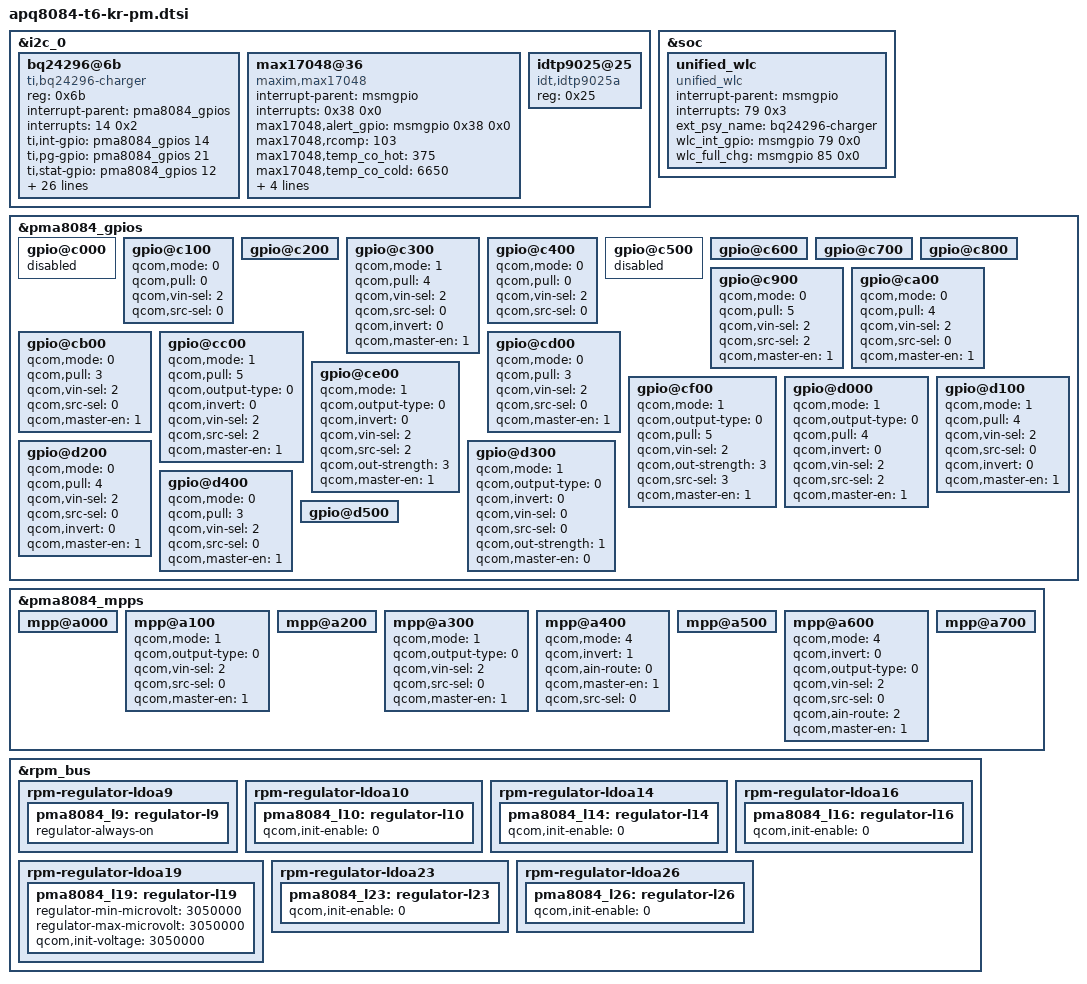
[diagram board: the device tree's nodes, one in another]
/* Copyright (c) 2012, Code Aurora Forum. All rights reserved.
 *
 * This program is free software; you can redistribute it and/or modify
* it under the terms of the GNU General Public License version 2 and
* only version 2 as published by the Free Software Foundation.
*
* This program is distributed in the hope that it will be useful,
* but WITHOUT ANY WARRANTY; without even the implied warranty of
* MERCHANTABILITY or FITNESS FOR A PARTICULAR PURPOSE.  See the
* GNU General Public License for more details.
*/
&i2c_0 {
	bq24296@6b {
		status = "ok";
		compatible = "ti,bq24296-charger";
		reg = <0x6b>;
		interrupt-parent = <&pma8084_gpios>;
		interrupts = <14 0x2>;
		ti,int-gpio = <&pma8084_gpios 14 0x0>;
		ti,pg-gpio = <&pma8084_gpios 21 0x0>;
		ti,stat-gpio = <&pma8084_gpios 12 0x02>;
		ti,ext-chg-en-gpio = <&pma8084_gpios 18 0x0>;
		ti,otg-en-gpio = <&msmgpio 127 0x0>;
		ti,chg-current-ma = <2000>;
		ti,term-current-ma = <128>;
		ti,vbat-max-mv = <4352>;
		ti,pre-chg-current-ma = <512>;
		ti,sys-vmin-mv = <3600>;
		ti,vin-limit-mv = <4520>;
		ti,icl-vbus-mv = <4400>;
		ti,pre-input-current-ma = <1000>;

		lge,no-init-cable = <0 0 0>;
		lge,cable-mhl-1k = <5000 500 500>;
		lge,cable-u-28p7k = <5500 2000 500>;
		lge,cable-28p7k = <6000 2000 500>;
		lge,cable-56k = <178000 2000 1500>;
		lge,cable-100k = <178500 2000 500>;
		lge,cable-130k = <340000 500 500>;
		lge,cable-180k = <400000 2000 500>;
		lge,cable-200k = <410000 2000 500>;
		lge,cable-220k = <485000 2000 500>;
		lge,cable-270k = <560000 2000 500>;
		lge,cable-330k = <735000 2000 500>;
		lge,cable-620k = <955000 2000 500>;
		lge,cable-910k = <1200000 2000 1500>;
		lge,cable-none = <1900000 2000 500>;

		qcom,bq24296-vadc = <&pma8084_vadc>;
	};
};

&i2c_0 {
	/* BLSP1 QUP3 */
	max17048@36 {
		compatible = "maxim,max17048";
		interrupt-parent = <&msmgpio>;
		interrupts = <0x38 0x0>;
		max17048,alert_gpio = <&msmgpio 0x38 0x0>;
		max17048,rcomp = <103>;
		max17048,temp_co_hot = <375>;
		max17048,temp_co_cold = <6650>;
		max17048,alert_threshold = <0x2>;
		max17048,full_design = <0xbb8>;
		max17048,empty = <0>;
		reg = <0x36>;
	};

	idtp9025@25 {
		status = "ok";
		compatible = "idt,idtp9025a";
		reg = <0x25>;
	};
};

&soc {
	unified_wlc {
		status = "ok";
		compatible = "unified_wlc";
		interrupt-parent = <&msmgpio>;
		interrupts = <79 0x3>;
		ext_psy_name = "bq24296-charger";
		wlc_int_gpio = <&msmgpio 79 0x0>;
		wlc_full_chg = <&msmgpio 85 0x0>;
	};
};

&pma8084_gpios {
	gpio@c000 { /* GPIO 1 */
		status = "disable";
	};

	gpio@c100 { /* GPIO 2 */
		status = "ok";           /* KYPD_VOL_UP_N */
		qcom,mode = <0>;
		qcom,pull = <0>;
		qcom,vin-sel = <2>;
		qcom,src-sel = <0>;
	};

	gpio@c200 { /* GPIO 3 */
		status = "ok";           /* DIVCLK1_REQ */
	};

	gpio@c300 { /* GPIO 4 */
		status = "ok";           /* BT_RESET_N */
		qcom,mode = <1>;         /* Digital output*/
		qcom,pull = <4>;         /* Pulldown 10uA */
		qcom,vin-sel = <2>;      /* VIN2 */
		qcom,src-sel = <0>;      /* GPIO */
		qcom,invert = <0>;       /* Invert */
		qcom,master-en = <1>;    /* Enable GPIO */
	};

	gpio@c400 { /* GPIO 5 */
		status = "ok";           /* KYPD_VOL_DOWN_N */
		qcom,mode = <0>;
		qcom,pull = <0>;
		qcom,vin-sel = <2>;
		qcom,src-sel = <0>;
	};

	gpio@c500 { /* GPIO 6 */
		status = "disable";
	};

	gpio@c600 { /* GPIO 7 */
		status = "ok";           /* RED_LED_DRV */
	};

	gpio@c700 { /* GPIO 8 */
		status = "ok";           /* GREEN_LED_DRV */
	};

	gpio@c800 { /* GPIO 9 */
		status = "ok";           /* BLUE_LED_DRV */
	};

	gpio@c900 { /* GPIO 10 */
		status = "ok";           /* NFC_CLK_REQ */
		qcom,mode = <0>;         /* QPNP_PIN_MODE_DIG_IN */
		qcom,pull = <5>;         /* QPNP_PIN_PULL_NO */
		qcom,vin-sel = <2>;      /* QPNP_PIN_VIN2 */
		qcom,src-sel = <2>;      /* QPNP_PIN_SEL_FUNC_1 */
		qcom,master-en = <1>;
	};

	gpio@ca00 { /* GPIO 11 */
		status = "ok";           /* SLIMPORT_CBL_DET */
		qcom,mode = <0>;         /* QPNP_PIN_MODE_DIG_IN */
		qcom,pull = <4>;         /* QPNP_PIN_PULL_DN */
		qcom,vin-sel = <2>;      /* QPNP_PIN_VIN2 */
		qcom,src-sel = <0>;      /* QPNP_PIN_SEL_FUNC_1 */
		qcom,master-en = <1>;
	};

	gpio@cb00 { /* GPIO 12 */
		status = "ok";           /* EXT_CHG_STAT */
		qcom,mode = <0>;         /* QPNP_PIN_MODE_DIG_IN */
		qcom,pull = <3>;         /* QPNP_PIN_GPIO_PULL_UP_1P5_30 */
		qcom,vin-sel = <2>;      /* QPNP_PIN_VIN2 */
		qcom,src-sel = <0>;      /* QPNP_PIN_SEL_FUNC_CONSTANT */
		qcom,master-en = <1>;
	};

	gpio@cc00 { /* GPIO 13 */
		status = "ok";           /* ANX_PDWN_CTL */
		qcom,mode = <1>;         /* Digital output */
		qcom,pull = <5>;         /* QPNP_PIN_PULL_NO */
		qcom,output-type = <0>;  /* CMOS logic */
		qcom,invert = <0>;       /* Output low initially */
		qcom,vin-sel = <2>;      /* VIN 2 */
		qcom,src-sel = <2>;      /* Function 1 */
		qcom,master-en = <1>;    /* Enable GPIO */
	};

	gpio@cd00 { /* GPIO 14 */
		status = "ok";           /* EXT_CHG_INT */
		qcom,mode = <0>;         /* QPNP_PIN_MODE_DIG_IN */
		qcom,pull = <3>;         /* QPNP_PIN_GPIO_PULL_UP_1P5_30 */
		qcom,vin-sel = <2>;      /* QPNP_PIN_VIN2 */
		qcom,src-sel = <0>;      /* QPNP_PIN_SEL_FUNC_CONSTANT */
		qcom,master-en = <1>;
	};

	gpio@ce00 { /* GPIO 15 */
		status = "ok";           /* CODEC_MCLK */
		qcom,mode = <1>;         /* Digital output */
		qcom,output-type = <0>;  /* CMOS logic */
		qcom,invert = <0>;       /* Output low initially */
		qcom,vin-sel = <2>;      /* VIN 2 */
		qcom,src-sel = <2>;      /* Function 1 */
		qcom,out-strength = <3>; /* High */
		qcom,master-en = <1>;    /* Enable GPIO */
	};

	gpio@cf00 { /* GPIO 16 */
		status = "ok";           /* WIFI_SLEEP_CLK, T6 BT Bringup kyungrin.seo */
		qcom,mode = <1>;
		qcom,output-type = <0>;
		qcom,pull = <5>;
		qcom,vin-sel = <2>;
		qcom,out-strength = <3>;
		qcom,src-sel = <3>;
		qcom,master-en = <1>;

	};

	gpio@d000 { /* GPIO 17 */
		status = "ok";           /* SLIMPORT_RESET_N */
		qcom,mode = <1>;         /* Digital output */
		qcom,output-type = <0>;  /* CMOS logic */
		qcom,pull = <4>;         /* QPNP_PIN_PULL_DN */
		qcom,invert = <0>;       /* Output low initially */
		qcom,vin-sel = <2>;      /* VIN 2 */
		qcom,src-sel = <2>;      /* Function 1 */
		qcom,master-en = <1>;    /* Enable GPIO */
	};

	gpio@d100 { /* GPIO 18 */
		status = "ok";           /* EXT_CHG_EN */
		qcom,mode = <1>;         /* Digital output*/
		qcom,pull = <4>;         /* Pulldown 10uA */
		qcom,vin-sel = <2>;      /* VIN2 */
		qcom,src-sel = <0>;      /* GPIO */
		qcom,invert = <0>;       /* Invert */
		qcom,master-en = <1>;    /* Enable GPIO */
	};

	gpio@d200 { /* GPIO 19 */
		status = "ok";           /* BOOST_BYP_BYP_N */
		qcom,mode = <0>;         /* QPNP_PIN_MODE_DIG_IN */
		qcom,pull = <4>;         /* QPNP_PIN_PULL_DN */
		qcom,vin-sel = <2>;      /* VIN2 */
		qcom,src-sel = <0>;      /* GPIO */
		qcom,invert = <0>;       /* Invert */
		qcom,master-en = <1>;    /* Enable GPIO */
	};

	gpio@d300 { /* GPIO 20 */
		status = "ok";           /* WIFI_SLEEP_CLK */
		qcom,mode = <1>;         /* Digital output */
		qcom,output-type = <0>;  /* CMOS logic */
		qcom,invert = <0>;       /* Do not invert the output */
		qcom,vin-sel = <0>;      /* VPH_PWR */
		qcom,src-sel = <0>;      /* GPIO */
		qcom,out-strength = <1>; /* High drive strength */
		qcom,master-en = <0>;    /* Enable GPIO */          /* WIFI_SLEEP_CLK, T6 WiFi Bringup. Set master-en = <0>;  */
	};

	gpio@d400 { /* GPIO 21 */
		status = "ok";           /* EXT_CHG_PG */
		qcom,mode = <0>;         /* QPNP_PIN_MODE_DIG_IN */
		qcom,pull = <3>;         /* QPNP_PIN_GPIO_PULL_UP_1P5_30 */
		qcom,vin-sel = <2>;      /* QPNP_PIN_VIN2 */
		qcom,src-sel = <0>;      /* QPNP_PIN_SEL_FUNC_CONSTANT */
		qcom,master-en = <1>;
	};

	gpio@d500 { /* GPIO 22 */
		status = "ok";           /* BATT_UIM_ALARM */
	};
};

&pma8084_mpps {
	mpp@a000 { /* MPP 1 */
	};

	mpp@a100 { /* MPP 2 */
		qcom,mode = <1>;         /* Digital output */
		qcom,output-type = <0>;  /* CMOS logic */
		qcom,vin-sel = <2>;      /* VIN 2 */
		qcom,src-sel = <0>;      /* Constant */
		qcom,master-en = <1>;    /* Enable GPIO */
	};

	mpp@a200 { /* MPP 3 */
	};

	mpp@a300 { /* MPP 4 */
		qcom,mode = <1>;         /* Digital output */
		qcom,output-type = <0>;  /* CMOS logic */
		qcom,vin-sel = <2>;      /* VIN 2 */
		qcom,src-sel = <0>;      /* Constant */
		qcom,master-en = <1>;    /* Enable GPIO */
	};

	mpp@a400 { /* MPP 5 */
		qcom,mode = <4>;		/* QPNP_PIN_MODE_AIN */
		qcom,invert = <1>;		/* Enable MPP */
		qcom,ain-route = <0>;	/* QPNP_PIN_AIN_AMUX_CH5 */
		qcom,master-en = <1>;
		qcom,src-sel = <0>;	/* QPNP_PIN_SEL_FUNC_CONSTANT */
	};

	mpp@a500 { /* MPP 6 */
	};

	mpp@a600 { /* MPP 7 */
		qcom,mode = <4>;
		qcom,invert = <0>;
		qcom,output-type = <0>;
		qcom,vin-sel = <2>;
		qcom,src-sel = <0>;
		qcom,ain-route = <2>;
		qcom,master-en = <1>;
	};

	mpp@a700 { /* MPP 8 */
	};
};

&rpm_bus {
	rpm-regulator-ldoa9 {
		status = "okay";
		pma8084_l9: regulator-l9 {
			regulator-always-on;
			status = "okay";
		};
	};
	rpm-regulator-ldoa10 {
		status = "okay";
		pma8084_l10: regulator-l10 {
			qcom,init-enable = <0>;
			status = "okay";
		};
	};
	rpm-regulator-ldoa14 {
		status = "okay";
		pma8084_l14: regulator-l14 {
			qcom,init-enable = <0>;
			status = "okay";
		};
	};
	rpm-regulator-ldoa16 {
		status = "okay";
		pma8084_l16: regulator-l16 {
			qcom,init-enable = <0>;
			status = "okay";
		};
	};
	rpm-regulator-ldoa19 {
		pma8084_l19: regulator-l19 {
			regulator-min-microvolt = <3050000>;
			regulator-max-microvolt = <3050000>;
			qcom,init-voltage = <3050000>;
			status = "okay";
		};
	};
	rpm-regulator-ldoa23 {
		status = "okay";
		pma8084_l23: regulator-l23 {
			qcom,init-enable = <0>;
			status = "okay";
		};
	};
	rpm-regulator-ldoa26 {
		status = "okay";
		pma8084_l26: regulator-l26 {
			qcom,init-enable = <0>;
			status = "okay";
		};
	};
};
